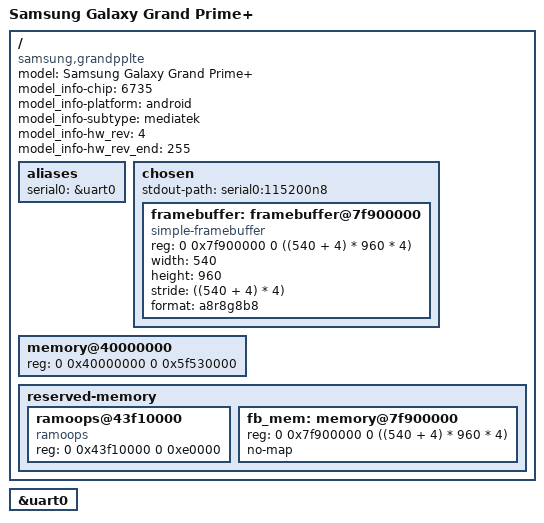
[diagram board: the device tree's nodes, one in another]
// SPDX-License-Identifier: BSD-3-Clause
/*
 * Copyright (c) 2021, Yassine Oudjana <y.oudjana@protonmail.com>
 */

/dts-v1/;

#include "mt6735.dtsi"

/ {
	model = "Samsung Galaxy Grand Prime+";
	compatible = "samsung,grandpplte", "mediatek,mt6735";

	/* model_info properties needed for dt.img packing */
	/* TODO: Remove these once U-Boot is ready */
	model_info-chip = <6735>;
	model_info-platform = "android";
	model_info-subtype = "mediatek";
	model_info-hw_rev = <4>;
	model_info-hw_rev_end = <255>;

	aliases {
		serial0 = &uart0;
	};

	chosen {
		#address-cells = <2>;
		#size-cells = <2>;
		ranges;

		stdout-path = "serial0:115200n8";

		framebuffer: framebuffer@7f900000 {
			compatible = "simple-framebuffer";
			reg = <0 0x7f900000 0 ((540 + 4) * 960 * 4)>;
			width = <540>;
			height = <960>;
			/* Lines have 4 pixels of padding */
			stride = <((540 + 4) * 4)>;
			format = "a8r8g8b8";
		};
	};

	memory@40000000 {
		device_type = "memory";
		reg = <0 0x40000000 0 0x5f530000>;
	};

	reserved-memory {
		ramoops@43f10000 {
			compatible = "ramoops";
			reg = <0 0x43f10000 0 0xe0000>;
		};

		fb_mem: memory@7f900000 {
			reg = <0 0x7f900000 0 ((540 + 4) * 960 * 4)>;
			no-map;
		};
	};
};

&uart0 {
	status = "okay";
};
